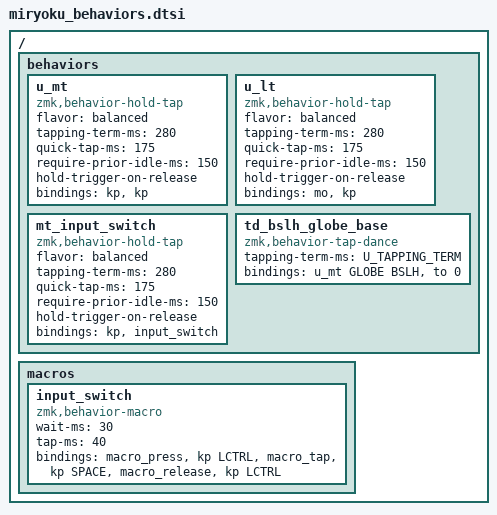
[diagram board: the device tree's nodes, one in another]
// Copyright 2022 Manna Harbour
// https://github.com/manna-harbour/miryoku

/ {
  behaviors {
    // urob-style hold-tap (5 of 6 knobs; omits per-hand
    // hold-trigger-key-positions which would require splitting u_mt into
    // hrm_l/hrm_r + overriding BASE/EXTRA/TAP alphas). Most of urob's
    // misfire-prevention comes from require-prior-idle-ms + balanced.
    //   - balanced: hold only if the partner key presses AND releases
    //   - 280ms term: wide enough that the idle/release checks do the work
    //   - quick-tap 175ms: repeating the same key forces a tap (no stray mod)
    //   - require-prior-idle 150ms: during rolling typing, always tap
    //   - hold-trigger-on-release: decide on partner release, not press
    u_mt: u_mt {
      compatible = "zmk,behavior-hold-tap";
      #binding-cells = <2>;
      flavor = "balanced";
      tapping-term-ms = <280>;
      quick-tap-ms = <175>;
      require-prior-idle-ms = <150>;
      hold-trigger-on-release;
      bindings = <&kp>, <&kp>;
    };
    u_lt: u_lt {
      compatible = "zmk,behavior-hold-tap";
      #binding-cells = <2>;
      flavor = "balanced";
      tapping-term-ms = <280>;
      quick-tap-ms = <175>;
      require-prior-idle-ms = <150>;
      hold-trigger-on-release;
      bindings = <&mo>, <&kp>;
    };
    mt_input_switch: mt_input_switch {
      compatible = "zmk,behavior-hold-tap";
      #binding-cells = <2>;
      flavor = "balanced";
      tapping-term-ms = <280>;
      quick-tap-ms = <175>;
      require-prior-idle-ms = <150>;
      hold-trigger-on-release;
      bindings = <&kp>, <&input_switch>;
    };
    td_bslh_globe_base: td_bslh_globe_base {
      compatible = "zmk,behavior-tap-dance";
      #binding-cells = <0>;
      tapping-term-ms = <U_TAPPING_TERM>;
      bindings = <&u_mt GLOBE BSLH>, <&to 0>;
    };
  };
  macros {
    input_switch: input_switch {
      compatible = "zmk,behavior-macro";
      #binding-cells = <0>;
      wait-ms = <30>;
      tap-ms = <40>;
      bindings = <&macro_press &kp LCTRL>, <&macro_tap &kp SPACE>, <&macro_release &kp LCTRL>;
    };
  };
};
